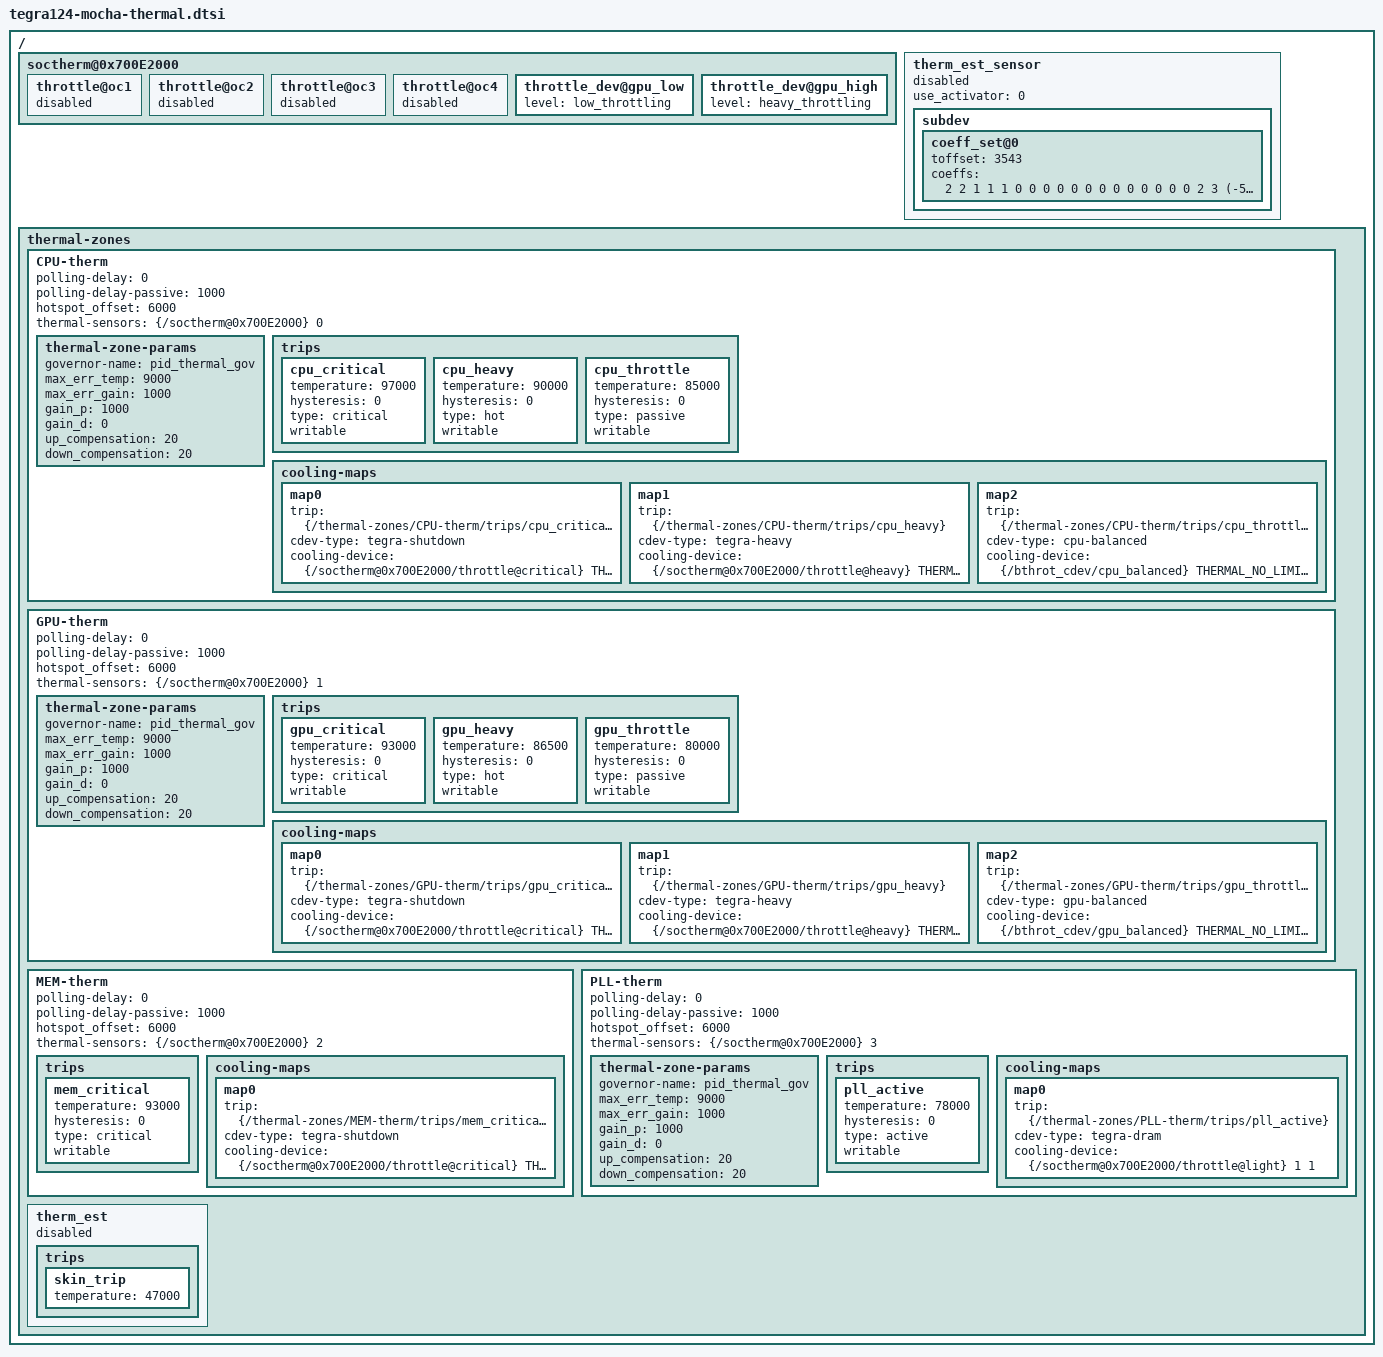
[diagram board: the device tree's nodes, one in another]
/ {
	soctherm@0x700E2000 {
		throttle@oc1 {
			status = "disabled";
		};
		throttle@oc2 {
			status = "disabled";
		};
		throttle@oc3 {
			status = "disabled";
		};
		throttle@oc4 {
			status = "disabled";
		};
		throttle_dev@gpu_low {
			level = "low_throttling";
		};
		throttle_dev@gpu_high {
			level = "heavy_throttling";
		};
	};

	therm_est_sensor {
		status = "disabled";
		use_activator = <0>;
		subdev {
			coeff_set@0 {
				toffset = <3543>;
				coeffs = <
					2 2 1 1 1 0 0 0 0 0 0 0 0 0 0 0 0 0 2 3
					(-5) 1 0 1 1 0 1 1 0 2 (-1) 1 2 3 3 2 2 1 8 53
				>;
			};
		};
	};

	thermal-zones {
		CPU-therm {
			status 			= "okay";
			polling-delay		= <0>;
			polling-delay-passive	= <1000>;
			hotspot_offset		= <6000>;
			thermal-sensors		= <&{/soctherm@0x700E2000} 0>;
			thermal-zone-params {
				governor-name = "pid_thermal_gov";
				max_err_temp = <9000>;
				max_err_gain = <1000>;
				gain_p = <1000>;
				gain_d = <0>;
				up_compensation = <20>;
				down_compensation = <20>;
			};
			trips {
				cpu_critical {
					temperature = <97000>;
					hysteresis = <0>;
					type = "critical";
					writable;
				};
				cpu_heavy {
					temperature = <90000>;
					hysteresis = <0>;
					type = "hot";
					writable;
				};
				cpu_throttle {
					temperature = <85000>;
					hysteresis = <0>;
					type = "passive";
					writable;
				};
			};
			cooling-maps {
				map0 {
					trip = <&{/thermal-zones/CPU-therm/trips/cpu_critical}>;
					cdev-type = "tegra-shutdown";
					cooling-device = <&{/soctherm@0x700E2000/throttle@critical}
						THERMAL_NO_LIMIT THERMAL_NO_LIMIT>;
				};
				map1 {
					trip = <&{/thermal-zones/CPU-therm/trips/cpu_heavy}>;
					cdev-type = "tegra-heavy";
					cooling-device = <&{/soctherm@0x700E2000/throttle@heavy}
						THERMAL_NO_LIMIT THERMAL_NO_LIMIT>;
				};
				map2 {
					trip = <&{/thermal-zones/CPU-therm/trips/cpu_throttle}>;
					cdev-type = "cpu-balanced";
					cooling-device = <&{/bthrot_cdev/cpu_balanced}
						THERMAL_NO_LIMIT THERMAL_NO_LIMIT>;
				};
			};
		};

		GPU-therm {
			status		 	= "okay";
			polling-delay		= <0>;
			polling-delay-passive	= <1000>;
			hotspot_offset		= <6000>;
			thermal-sensors		= <&{/soctherm@0x700E2000} 1>;
			thermal-zone-params {
				governor-name = "pid_thermal_gov";
				max_err_temp = <9000>;
				max_err_gain = <1000>;
				gain_p = <1000>;
				gain_d = <0>;
				up_compensation = <20>;
				down_compensation = <20>;
			};
			trips {
				gpu_critical {
					temperature = <93000>;
					hysteresis = <0>;
					type = "critical";
					writable;
				};
				gpu_heavy {
					temperature = <86500>;
					hysteresis = <0>;
					type = "hot";
					writable;
				};
				gpu_throttle {
					temperature = <80000>;
					hysteresis = <0>;
					type = "passive";
					writable;
				};
			};
			cooling-maps {
				map0 {
					trip = <&{/thermal-zones/GPU-therm/trips/gpu_critical}>;
					cdev-type = "tegra-shutdown";
					cooling-device = <&{/soctherm@0x700E2000/throttle@critical}
						THERMAL_NO_LIMIT THERMAL_NO_LIMIT>;
				};
				map1 {
					trip = <&{/thermal-zones/GPU-therm/trips/gpu_heavy}>;
					cdev-type = "tegra-heavy";
					cooling-device = <&{/soctherm@0x700E2000/throttle@heavy}
						THERMAL_NO_LIMIT THERMAL_NO_LIMIT>;
				};
				map2 {
					trip = <&{/thermal-zones/GPU-therm/trips/gpu_throttle}>;
					cdev-type = "gpu-balanced";
					cooling-device = <&{/bthrot_cdev/gpu_balanced}
						THERMAL_NO_LIMIT THERMAL_NO_LIMIT>;
				};
			};
		};
		
		MEM-therm {
			status 			= "okay";
			polling-delay		= <0>;
			polling-delay-passive	= <1000>;
			hotspot_offset		= <6000>;
			thermal-sensors		= <&{/soctherm@0x700E2000} 2>;
			trips {
				mem_critical {
					temperature = <93000>;
					hysteresis = <0>;
					type = "critical";
					writable;
				};
			};
			cooling-maps {
				map0 {
					trip = <&{/thermal-zones/MEM-therm/trips/mem_critical}>;
					cdev-type = "tegra-shutdown";
					cooling-device = <&{/soctherm@0x700E2000/throttle@critical}
						THERMAL_NO_LIMIT THERMAL_NO_LIMIT>;
				};
			};
		};

		PLL-therm {
			status 			= "okay";
			polling-delay		= <0>;
			polling-delay-passive	= <1000>;
			hotspot_offset		= <6000>;
			thermal-sensors		= <&{/soctherm@0x700E2000} 3>;
			thermal-zone-params {
				governor-name = "pid_thermal_gov";
				max_err_temp = <9000>;
				max_err_gain = <1000>;
				gain_p = <1000>;
				gain_d = <0>;
				up_compensation = <20>;
				down_compensation = <20>;
			};
			trips {
				pll_active {
					temperature = <78000>;
					hysteresis = <0>;
					type = "active";
					writable;
				};
			};
			cooling-maps {
				map0 {
					trip = <&{/thermal-zones/PLL-therm/trips/pll_active}>;
					cdev-type = "tegra-dram";
					cooling-device = <&{/soctherm@0x700E2000/throttle@light} 1 1>;
				};
			};
		};

		therm_est {
			status = "disabled";
			trips {
				skin_trip {
					temperature = <47000>;
				};
			};
		};
	};
};
